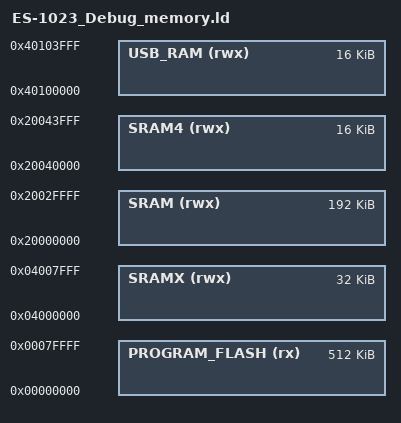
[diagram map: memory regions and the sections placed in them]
/*
 * GENERATED FILE - DO NOT EDIT
 * Copyright (c) 2008-2013 Code Red Technologies Ltd,
 * Copyright 2015, 2018-2019 NXP
 * (c) NXP Semiconductors 2013-2023
 * Generated linker script file for LPC5528
 * Created from memory.ldt by FMCreateLinkMemory
 * Using Freemarker v2.3.30
 * MCUXpresso IDE v11.6.1 [Build 8255] [2022-10-03] on Feb 8, 2023, 12:06:29 PM
 */

MEMORY
{
  /* Define each memory region */
  PROGRAM_FLASH (rx) : ORIGIN = 0x0, LENGTH = 0x80000 /* 512K bytes (alias Flash) */  
  SRAM (rwx) : ORIGIN = 0x20000000, LENGTH = 0x30000 /* 192K bytes (alias RAM) */  
  SRAMX (rwx) : ORIGIN = 0x4000000, LENGTH = 0x8000 /* 32K bytes (alias RAM2) */  
  USB_RAM (rwx) : ORIGIN = 0x40100000, LENGTH = 0x4000 /* 16K bytes (alias RAM3) */  
  SRAM4 (rwx) : ORIGIN = 0x20040000, LENGTH = 0x4000 /* 16K bytes (alias RAM4) */  
}

  /* Define a symbol for the top of each memory region */
  __base_PROGRAM_FLASH = 0x0  ; /* PROGRAM_FLASH */  
  __base_Flash = 0x0 ; /* Flash */  
  __top_PROGRAM_FLASH = 0x0 + 0x80000 ; /* 512K bytes */  
  __top_Flash = 0x0 + 0x80000 ; /* 512K bytes */  
  __base_SRAM = 0x20000000  ; /* SRAM */  
  __base_RAM = 0x20000000 ; /* RAM */  
  __top_SRAM = 0x20000000 + 0x30000 ; /* 192K bytes */  
  __top_RAM = 0x20000000 + 0x30000 ; /* 192K bytes */  
  __base_SRAMX = 0x4000000  ; /* SRAMX */  
  __base_RAM2 = 0x4000000 ; /* RAM2 */  
  __top_SRAMX = 0x4000000 + 0x8000 ; /* 32K bytes */  
  __top_RAM2 = 0x4000000 + 0x8000 ; /* 32K bytes */  
  __base_USB_RAM = 0x40100000  ; /* USB_RAM */  
  __base_RAM3 = 0x40100000 ; /* RAM3 */  
  __top_USB_RAM = 0x40100000 + 0x4000 ; /* 16K bytes */  
  __top_RAM3 = 0x40100000 + 0x4000 ; /* 16K bytes */  
  __base_SRAM4 = 0x20040000  ; /* SRAM4 */  
  __base_RAM4 = 0x20040000 ; /* RAM4 */  
  __top_SRAM4 = 0x20040000 + 0x4000 ; /* 16K bytes */  
  __top_RAM4 = 0x20040000 + 0x4000 ; /* 16K bytes */  
